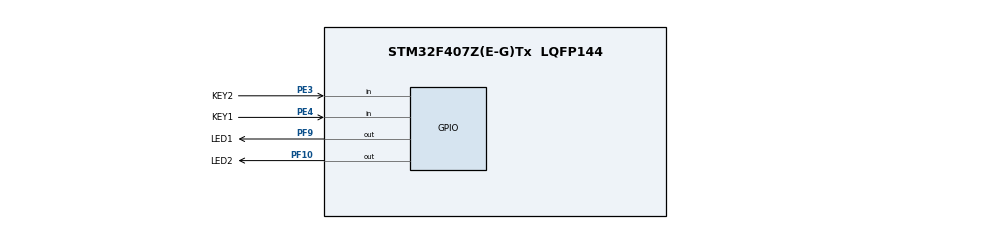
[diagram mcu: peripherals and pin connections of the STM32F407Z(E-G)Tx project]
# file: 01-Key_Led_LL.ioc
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Mcu.Family=STM32F4
Mcu.Name=STM32F407Z(E-G)Tx
Mcu.Package=LQFP144
NVIC.PriorityGroup=NVIC_PRIORITYGROUP_4
PA13.Mode=Serial_Wire
PA13.Signal=SYS_JTMS-SWDIO
PA14.Mode=Serial_Wire
PA14.Signal=SYS_JTCK-SWCLK
PE3.GPIO_Label=KEY2
PE3.GPIO_PuPd=GPIO_PULLUP
PE3.Signal=GPIO_Input
PE4.GPIO_Label=KEY1
PE4.GPIO_PuPd=GPIO_PULLUP
PE4.Signal=GPIO_Input
PF10.GPIO_Label=LED2
PF10.PinState=GPIO_PIN_SET
PF10.Signal=GPIO_Output
PF9.GPIO_Label=LED1
PF9.PinState=GPIO_PIN_SET
PF9.Signal=GPIO_Output
PH0-OSC_IN.Mode=HSE-External-Oscillator
PH0-OSC_IN.Signal=RCC_OSC_IN
PH1-OSC_OUT.Mode=HSE-External-Oscillator
PH1-OSC_OUT.Signal=RCC_OSC_OUT
ProjectManager.HeapSize=0x200
ProjectManager.StackSize=0x400
ProjectManager.TargetToolchain=MDK-ARM V5
RCC.AHBFreq_Value=16000000
RCC.APB1Freq_Value=16000000
RCC.APB2Freq_Value=16000000
RCC.CortexFreq_Value=16000000
RCC.HSE_VALUE=8000000
RCC.HSI_VALUE=16000000
RCC.LSE_VALUE=32768
RCC.SYSCLKFreq_VALUE=16000000
RCC.VCOOutputFreq_Value=192000000
board=custom

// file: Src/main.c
/* USER CODE BEGIN Header */
/**
  ******************************************************************************
  * @file           : main.c
  * @brief          : Main program body
  ******************************************************************************
  * @attention
  *
  * <h2><center>&copy; Copyright (c) 2019 STMicroelectronics.
  * All rights reserved.</center></h2>
  *
  * This software component is licensed by ST under BSD 3-Clause license,
  * the "License"; You may not use this file except in compliance with the
  * License. You may obtain a copy of the License at:
  *                        opensource.org/licenses/BSD-3-Clause
  *
  ******************************************************************************
  */
/* USER CODE END Header */

#include "main.h"
#include "gpio.h"

void SystemClock_Config(void);
/* USER CODE BEGIN PFP */

uint8_t Scan(void);

/* USER CODE END PFP */

int main(void)
{

  /* MCU Configuration--------------------------------------------------------*/

  /* Reset of all peripherals, Initializes the Flash interface and the Systick. */

  LL_APB2_GRP1_EnableClock(LL_APB2_GRP1_PERIPH_SYSCFG);
  LL_APB1_GRP1_EnableClock(LL_APB1_GRP1_PERIPH_PWR);

  NVIC_SetPriorityGrouping(NVIC_PRIORITYGROUP_4);

  /* System interrupt init*/

  /* Configure the system clock */
  SystemClock_Config();

  /* Initialize all configured peripherals */
  MX_GPIO_Init();

  /* Infinite loop */
  while (1)
  {

      uint8_t flag = Scan();
//      if((flag & 0x1) > 0)
//      {
//          LL_GPIO_TogglePin(LED1_GPIO_Port, LED1_Pin);
//      }
      if((flag & 0x2) > 0)
      {
          LL_GPIO_TogglePin(LED2_GPIO_Port, LED2_Pin);
      }

      LL_GPIO_TogglePin(LED1_GPIO_Port, LED1_Pin);
      LL_mDelay(200);

  }
}

void SystemClock_Config(void)
{
  LL_FLASH_SetLatency(LL_FLASH_LATENCY_0);

  if(LL_FLASH_GetLatency() != LL_FLASH_LATENCY_0)
  {
  Error_Handler();
  }
  LL_PWR_SetRegulVoltageScaling(LL_PWR_REGU_VOLTAGE_SCALE1);
  LL_RCC_HSI_SetCalibTrimming(16);
  LL_RCC_HSI_Enable();

   /* Wait till HSI is ready */
  while(LL_RCC_HSI_IsReady() != 1)
  {

  }
  LL_RCC_SetAHBPrescaler(LL_RCC_SYSCLK_DIV_1);
  LL_RCC_SetAPB1Prescaler(LL_RCC_APB1_DIV_1);
  LL_RCC_SetAPB2Prescaler(LL_RCC_APB2_DIV_1);
  LL_RCC_SetSysClkSource(LL_RCC_SYS_CLKSOURCE_HSI);

   /* Wait till System clock is ready */
  while(LL_RCC_GetSysClkSource() != LL_RCC_SYS_CLKSOURCE_STATUS_HSI)
  {

  }
  LL_Init1msTick(16000000);
  LL_SYSTICK_SetClkSource(LL_SYSTICK_CLKSOURCE_HCLK);
  LL_SetSystemCoreClock(16000000);
}

/* USER CODE BEGIN 4 */

uint8_t Scan(void)
{
    uint8_t flag = 0;

    if(LL_GPIO_IsInputPinSet(KEY1_GPIO_Port, KEY1_Pin) == 0)
    {
        LL_mDelay(20);
        if(LL_GPIO_IsInputPinSet(KEY1_GPIO_Port, KEY1_Pin) == 0)
            flag |= 0x1;
    }
    if(LL_GPIO_IsInputPinSet(KEY2_GPIO_Port, KEY2_Pin) == 0)
    {
        LL_mDelay(20);
        if(LL_GPIO_IsInputPinSet(KEY2_GPIO_Port, KEY2_Pin) == 0)
            flag |= 0x2;
    }
    return flag;
}

/* USER CODE END 4 */

void Error_Handler(void)
{
}

/************************ (C) COPYRIGHT STMicroelectronics *****END OF FILE****/
